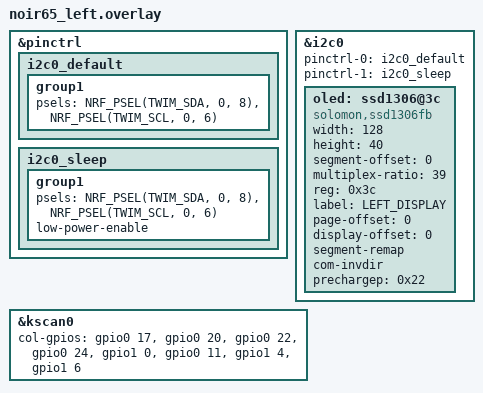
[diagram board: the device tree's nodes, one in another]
/*
 * Copyright (c) 2020 Pete Johanson
 *
 * SPDX-License-Identifier: MIT
 */

#include "noir65.dtsi"
#include <dt-bindings/led/led.h>

&pinctrl {
    // Other pinctrl definitions for other hardware
    i2c0_default: i2c0_default {
        group1 {
            psels = <NRF_PSEL(TWIM_SDA, 0, 8)>,
                    <NRF_PSEL(TWIM_SCL, 0, 6)>;
        };
    };

    i2c0_sleep: i2c0_sleep {
        group1 {
            psels = <NRF_PSEL(TWIM_SDA, 0, 8)>,
                    <NRF_PSEL(TWIM_SCL, 0, 6)>;
            low-power-enable;
        };
    };

};

&i2c0 {
	status = "okay";
	//compatible = "nordic,nrf-twi";
	pinctrl-0 = <&i2c0_default>;
	pinctrl-1 = <&i2c0_sleep>;
	pinctrl-names = "default", "sleep";
    
	oled: ssd1306@3c {
        // OLED 0.42，使用以下
        width = <128>;  //72*40 
		height = <40>;  //72*40 
        compatible = "solomon,ssd1306fb";   //OLED 0.42
        segment-offset = <0>;   //OLED 0.42
        multiplex-ratio = <39>; //72*40  
        //com-sequential; //OLED 0.42注销本行
        
        // OLED 0.91或OLED 0.96，使用以下
        //width = <128>;
		//height = <64>;    //128*64
		//height = <32>;    //128*32
        //compatible = "solomon,ssd1306fb";   //OLED 0.91, OLED 0.96
        //segment-offset = <0>;   //OLED 0.91, OLED 0.96
        //multiplex-ratio = <31>; //128*32
        //multiplex-ratio = <63>; //128*64
        //com-sequential; //OLED 0.91或OLED 0.96 启用本行

        // OLED 1.30，使用以下
        //width = <128>;
		//height = <64>;
        //compatible = "sinowealth,sh1106";   //OLED 1.30
        //segment-offset = <2>;   //OLED 1.30
		//multiplex-ratio = <63>; //128*64
        //com-sequential; // OLED1.30注销本行

		reg = <0x3c>;
		label = "LEFT_DISPLAY";
		page-offset = <0>;
		display-offset = <0>;
		segment-remap;
		com-invdir;
        //inversion-on;   // 翻转颜色
		prechargep = <0x22>;
        
	};
};


&kscan0 {
    col-gpios
        = <&gpio0 17 GPIO_ACTIVE_HIGH>
        , <&gpio0 20 GPIO_ACTIVE_HIGH>
        , <&gpio0 22 GPIO_ACTIVE_HIGH>
        , <&gpio0 24 GPIO_ACTIVE_HIGH>
        , <&gpio1 0 GPIO_ACTIVE_HIGH>
        , <&gpio0 11 GPIO_ACTIVE_HIGH>
        , <&gpio1 4 GPIO_ACTIVE_HIGH>
        , <&gpio1 6 GPIO_ACTIVE_HIGH>
        ;
    };
